VERSION ""

NS_ :

BS_:

BU_:

BO_ 645 Vehicle_info: 2 Vector__XXX
 SG_ LIn_Speed : 7|8@0+ (1,0) [0|0] "" Vector__XXX
 SG_ Ang_Speed : 15|8@0+ (1,0) [0|0] "" Vector__XXX

BO_ 145 sim_LocalPlannerPathRequest: 2 Vector__XXX
 SG_ Distance : 7|16@0+ (0.0153,0) [0|0] "cm" Vector__XXX

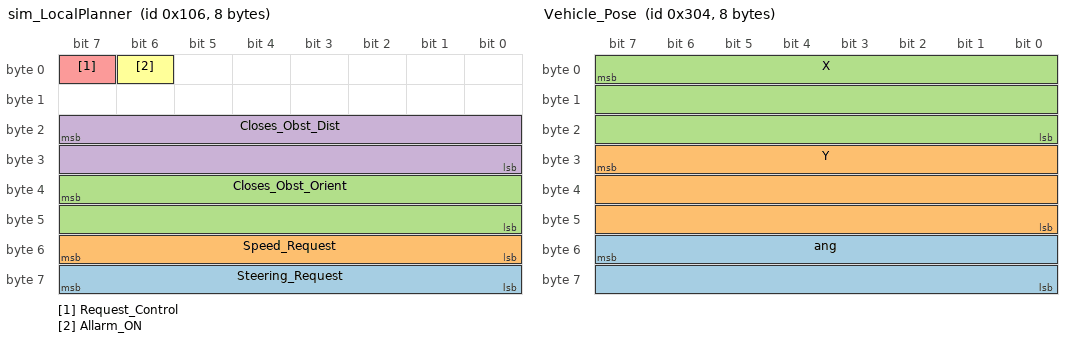
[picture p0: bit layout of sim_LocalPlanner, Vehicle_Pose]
BO_ 262 sim_LocalPlanner: 8 Vector__XXX
 SG_ Steering_Request : 63|8@0+ (1,0) [0|0] "" Vector__XXX
 SG_ Speed_Request : 55|8@0+ (1,0) [0|0] "" Vector__XXX
 SG_ Closes_Obst_Orient : 39|16@0+ (0.0055,0) [0|0] "deg" Vector__XXX
 SG_ Closes_Obst_Dist : 23|16@0+ (0.0061,0) [0|0] "cm" Vector__XXX
 SG_ Request_Control : 7|1@0+ (1,0) [0|1] "" Vector__XXX
 SG_ Allarm_ON : 6|1@0+ (1,0) [0|0] "" Vector__XXX

BO_ 772 Vehicle_Pose: 8 Vector__XXX
 SG_ ang : 55|16@0+ (0.0055,0) [0|0] "deg" Vector__XXX
 SG_ Y : 31|24@0+ (0.35,0) [0|0] "m" Vector__XXX
 SG_ X : 7|24@0+ (0.35,0) [0|0] "m" Vector__XXX

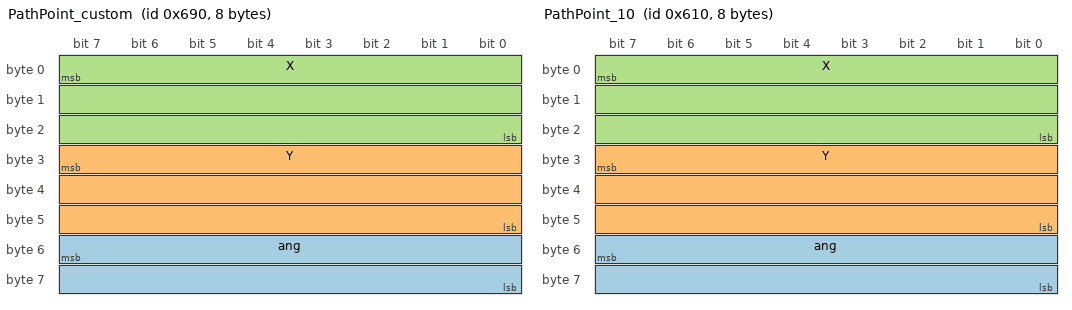
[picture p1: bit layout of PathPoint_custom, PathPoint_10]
BO_ 1680 PathPoint_custom: 8 Vector__XXX
 SG_ ang : 55|16@0+ (0.0055,0) [0|0] "deg" Vector__XXX
 SG_ Y : 31|24@0+ (0.35,0) [0|0] "m" Vector__XXX
 SG_ X : 7|24@0+ (0.35,0) [0|0] "m" Vector__XXX

BO_ 1552 PathPoint_10: 8 Vector__XXX
 SG_ ang : 55|16@0+ (0.0055,0) [0|0] "deg" Vector__XXX
 SG_ Y : 31|24@0+ (0.35,0) [0|0] "m" Vector__XXX
 SG_ X : 7|24@0+ (0.35,0) [0|0] "m" Vector__XXX

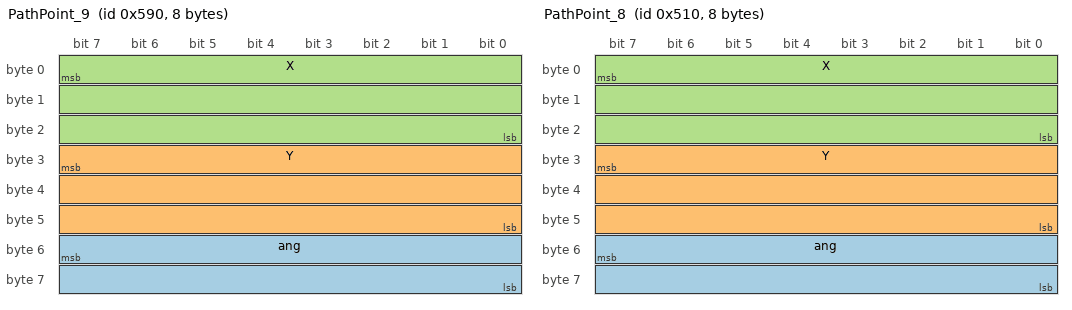
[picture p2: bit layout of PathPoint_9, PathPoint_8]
BO_ 1424 PathPoint_9: 8 Vector__XXX
 SG_ ang : 55|16@0+ (0.0055,0) [0|0] "deg" Vector__XXX
 SG_ Y : 31|24@0+ (0.35,0) [0|0] "m" Vector__XXX
 SG_ X : 7|24@0+ (0.35,0) [0|0] "m" Vector__XXX

BO_ 1296 PathPoint_8: 8 Vector__XXX
 SG_ ang : 55|16@0+ (0.0055,0) [0|0] "deg" Vector__XXX
 SG_ Y : 31|24@0+ (0.35,0) [0|0] "m" Vector__XXX
 SG_ X : 7|24@0+ (0.35,0) [0|0] "m" Vector__XXX

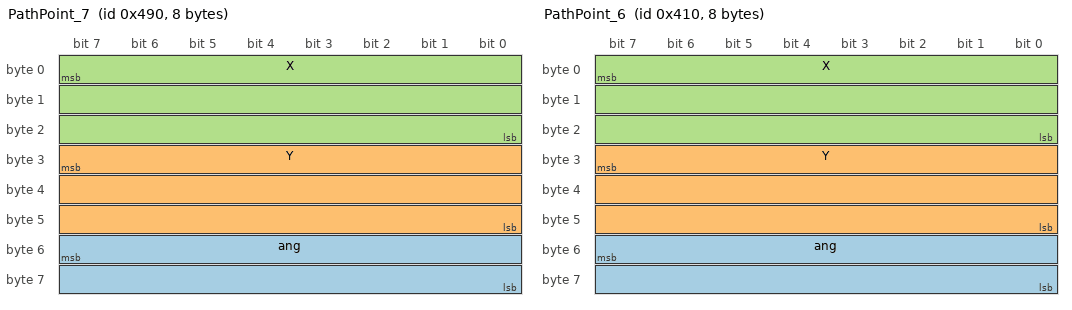
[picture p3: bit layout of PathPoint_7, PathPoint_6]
BO_ 1168 PathPoint_7: 8 Vector__XXX
 SG_ ang : 55|16@0+ (0.0055,0) [0|0] "deg" Vector__XXX
 SG_ Y : 31|24@0+ (0.35,0) [0|0] "m" Vector__XXX
 SG_ X : 7|24@0+ (0.35,0) [0|0] "m" Vector__XXX

BO_ 1040 PathPoint_6: 8 Vector__XXX
 SG_ ang : 55|16@0+ (0.0055,0) [0|0] "deg" Vector__XXX
 SG_ Y : 31|24@0+ (0.35,0) [0|0] "m" Vector__XXX
 SG_ X : 7|24@0+ (0.35,0) [0|0] "m" Vector__XXX

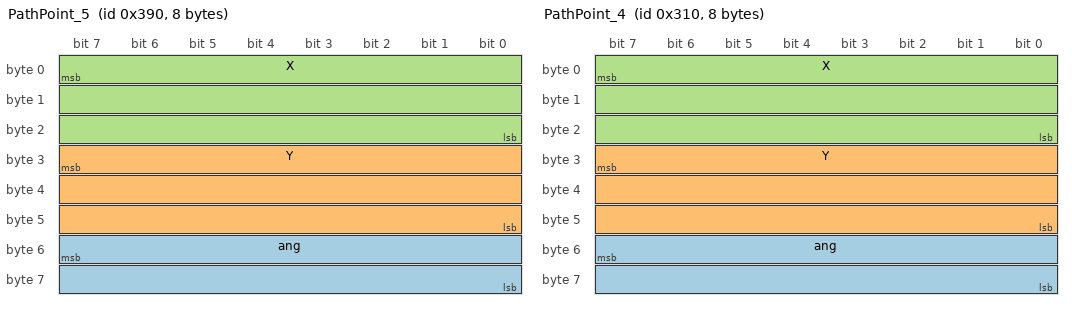
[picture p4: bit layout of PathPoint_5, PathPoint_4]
BO_ 912 PathPoint_5: 8 Vector__XXX
 SG_ ang : 55|16@0+ (0.0055,0) [0|0] "deg" Vector__XXX
 SG_ Y : 31|24@0+ (0.35,0) [0|0] "m" Vector__XXX
 SG_ X : 7|24@0+ (0.35,0) [0|0] "m" Vector__XXX

BO_ 784 PathPoint_4: 8 Vector__XXX
 SG_ ang : 55|16@0+ (0.0055,0) [0|0] "deg" Vector__XXX
 SG_ Y : 31|24@0+ (0.35,0) [0|0] "m" Vector__XXX
 SG_ X : 7|24@0+ (0.35,0) [0|0] "m" Vector__XXX

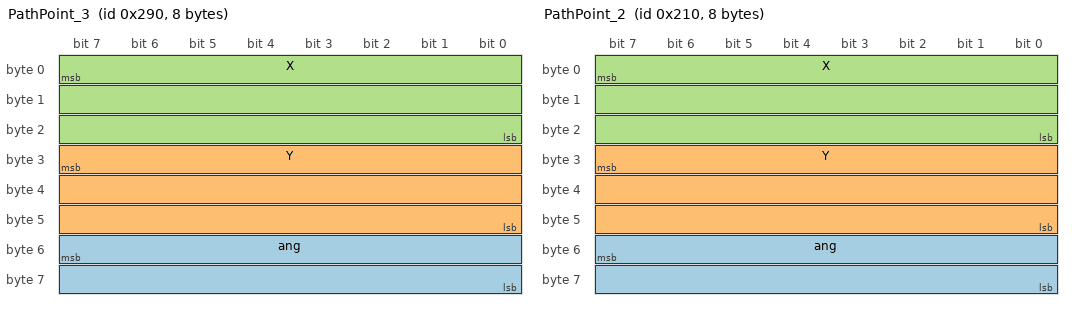
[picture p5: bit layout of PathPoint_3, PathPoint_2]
BO_ 656 PathPoint_3: 8 Vector__XXX
 SG_ ang : 55|16@0+ (0.0055,0) [0|0] "deg" Vector__XXX
 SG_ Y : 31|24@0+ (0.35,0) [0|0] "m" Vector__XXX
 SG_ X : 7|24@0+ (0.35,0) [0|0] "m" Vector__XXX

BO_ 528 PathPoint_2: 8 Vector__XXX
 SG_ ang : 55|16@0+ (0.0055,0) [0|0] "deg" Vector__XXX
 SG_ Y : 31|24@0+ (0.35,0) [0|0] "m" Vector__XXX
 SG_ X : 7|24@0+ (0.35,0) [0|0] "m" Vector__XXX

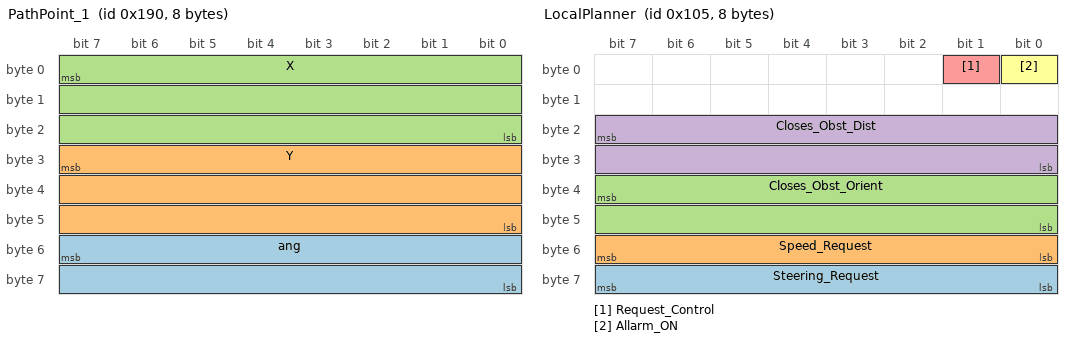
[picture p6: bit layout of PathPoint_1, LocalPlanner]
BO_ 400 PathPoint_1: 8 Vector__XXX
 SG_ ang : 55|16@0+ (0.0055,0) [0|0] "deg" Vector__XXX
 SG_ Y : 31|24@0+ (0.35,0) [0|0] "m" Vector__XXX
 SG_ X : 7|24@0+ (0.35,0) [0|0] "m" Vector__XXX

BO_ 144 LocalPlannerPathRequest: 2 Vector__XXX
 SG_ Distance : 7|16@0+ (0.0153,0) [0|0] "cm" Vector__XXX

BO_ 261 LocalPlanner: 8 Vector__XXX
 SG_ Steering_Request : 63|8@0+ (1,0) [0|0] "" Vector__XXX
 SG_ Speed_Request : 55|8@0+ (1,0) [0|0] "" Vector__XXX
 SG_ Closes_Obst_Orient : 39|16@0+ (0.0055,0) [0|0] "deg" Vector__XXX
 SG_ Closes_Obst_Dist : 23|16@0+ (0.0061,0) [0|0] "cm" Vector__XXX
 SG_ Request_Control : 1|1@0+ (1,0) [0|1] "" Vector__XXX
 SG_ Allarm_ON : 0|1@0+ (1,0) [0|0] "" Vector__XXX
